# ipc register map
Vendor: Texas Instruments
Peripheral module from a debugger description file (folder Keystone).
Registers are 32-bit, read-write, no defined reset value unless marked. A register's access mark holds for its fields unless they carry their own. Offsets are as the file gives them; lines under a group give offsets from that group; [hi:lo] are bit positions; {n}, {i} and the like mark numbered series; 'fields as' and 'values as' point back to an identical list; <NAME> marks a mode.

## IPC
0x00 nmigr — (1 of 8, stride 4)
  [0] nmig
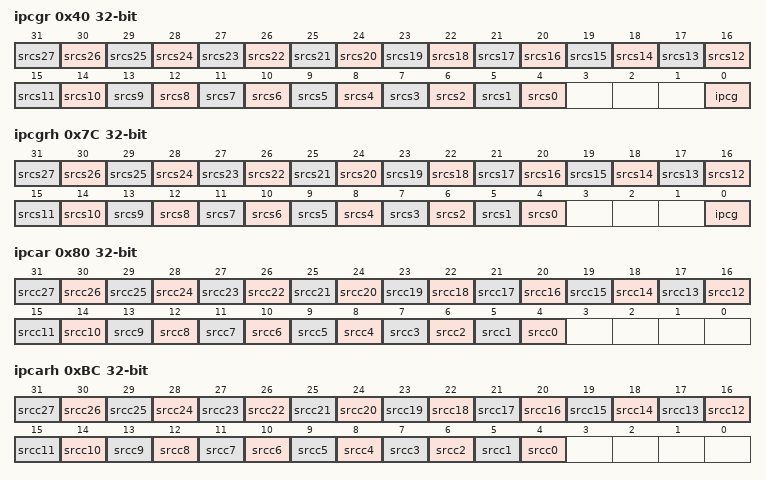
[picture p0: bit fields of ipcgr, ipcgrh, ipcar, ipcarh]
0x40 ipcgr — (1 of 8, stride 4)
  [n+4] srcs{n} (n=0..27), [0] ipcg
0x7C ipcgrh
  [n+4] srcs{n} (n=0..27), [0] ipcg
0x80 ipcar — (1 of 8, stride 4)
  [n+4] srcc{n} (n=0..27)
0xBC ipcarh
  [n+4] srcc{n} (n=0..27)
